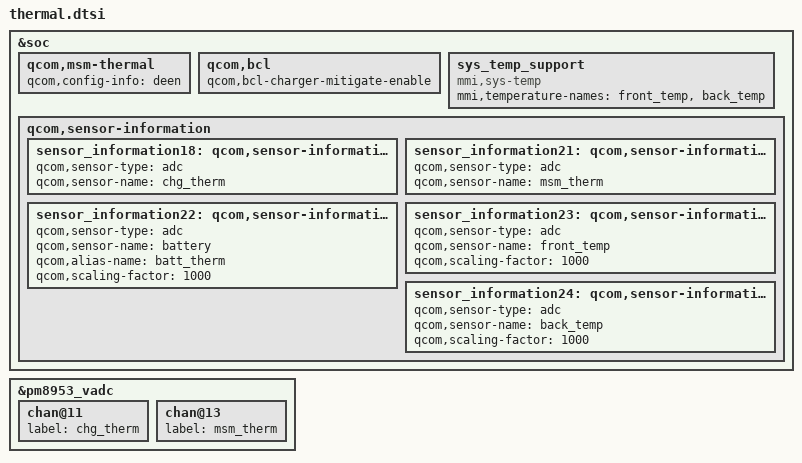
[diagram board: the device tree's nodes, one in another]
/* Copyright (c) 2018, Motorola Mobility Inc. All rights reserved.
 *
 * This program is free software; you can redistribute it and/or modify
 * it under the terms of the GNU General Public License version 2 and
 * only version 2 as published by the Free Software Foundation.
 *
 * This program is distributed in the hope that it will be useful,
 * but WITHOUT ANY WARRANTY; without even the implied warranty of
 * MERCHANTABILITY or FITNESS FOR A PARTICULAR PURPOSE.  See the
 * GNU General Public License for more details.
 */

&soc {
	qcom,msm-thermal {
		qcom,config-info = "deen";
	};

	qcom,bcl {
		qcom,bcl-charger-mitigate-enable;
	};

	sys_temp_support {
		compatible = "mmi,sys-temp";
		mmi,temperature-names = "front_temp",
					"back_temp";
		status = "ok";
	};

	qcom,sensor-information {
		sensor_information18: qcom,sensor-information-18 {
			qcom,sensor-type = "adc";
			qcom,sensor-name = "chg_therm";
		};

		sensor_information21: qcom,sensor-information-21 {
			qcom,sensor-type = "adc";
			qcom,sensor-name = "msm_therm";
		};

		sensor_information22: qcom,sensor-information-22 {
			qcom,sensor-type = "adc";
			qcom,sensor-name = "battery";
			qcom,alias-name  = "batt_therm";
			qcom,scaling-factor = <1000>;
		};
		sensor_information23: qcom,sensor-information-23 {
			qcom,sensor-type = "adc";
			qcom,sensor-name = "front_temp";
			qcom,scaling-factor = <1000>;
		};
		sensor_information24: qcom,sensor-information-24 {
			qcom,sensor-type = "adc";
			qcom,sensor-name = "back_temp";
			qcom,scaling-factor = <1000>;
		};
	};
};

&pm8953_vadc {
	chan@11 {
		label = "chg_therm";
	};

	chan@13 {
		label = "msm_therm";
	};
};
